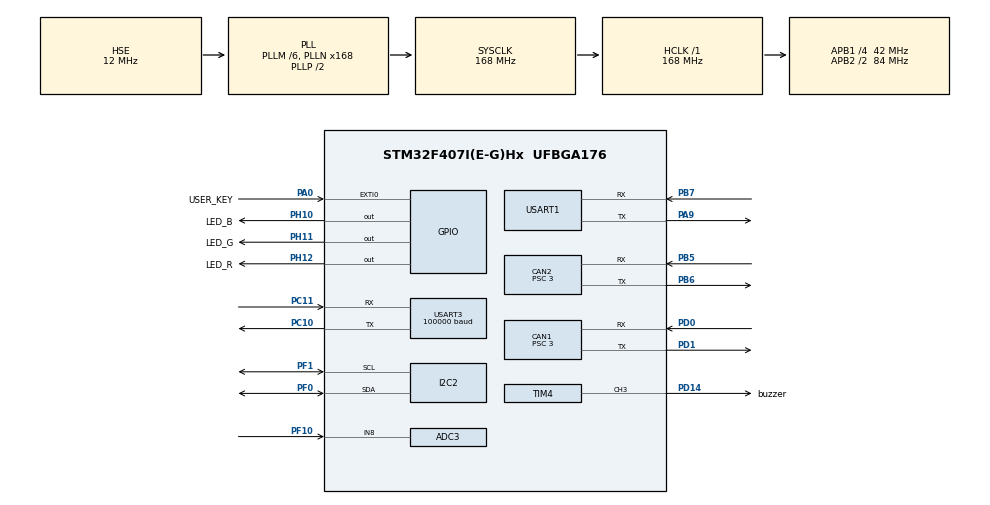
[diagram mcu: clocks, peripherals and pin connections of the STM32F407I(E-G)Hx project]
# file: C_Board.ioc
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ADC1.Channel-0\#ChannelRegularConversion=ADC_CHANNEL_VREFINT
ADC1.NbrOfConversionFlag=1
ADC1.Rank-0\#ChannelRegularConversion=1
ADC1.SamplingTime-0\#ChannelRegularConversion=ADC_SAMPLETIME_3CYCLES
ADC1.master=1
ADC3.Channel-0\#ChannelRegularConversion=ADC_CHANNEL_8
ADC3.NbrOfConversionFlag=1
ADC3.Rank-0\#ChannelRegularConversion=1
ADC3.SamplingTime-0\#ChannelRegularConversion=ADC_SAMPLETIME_3CYCLES
CAN1.BS1=CAN_BS1_10TQ
CAN1.BS2=CAN_BS2_3TQ
CAN1.CalculateTimeQuantum=71.42857142857143
CAN1.Prescaler=3
CAN2.BS1=CAN_BS1_10TQ
CAN2.BS2=CAN_BS2_3TQ
CAN2.CalculateTimeQuantum=71.42857142857143
CAN2.Prescaler=3
Dma.Request0=USART3_RX
Dma.USART3_RX.0.Direction=DMA_PERIPH_TO_MEMORY
Dma.USART3_RX.0.FIFOMode=DMA_FIFOMODE_DISABLE
Dma.USART3_RX.0.Instance=DMA1_Stream1
Dma.USART3_RX.0.MemDataAlignment=DMA_MDATAALIGN_BYTE
Dma.USART3_RX.0.MemInc=DMA_MINC_ENABLE
Dma.USART3_RX.0.Mode=DMA_NORMAL
Dma.USART3_RX.0.PeriphDataAlignment=DMA_PDATAALIGN_BYTE
Dma.USART3_RX.0.PeriphInc=DMA_PINC_DISABLE
Dma.USART3_RX.0.Priority=DMA_PRIORITY_VERY_HIGH
I2C2.I2C_Mode=I2C_Fast
Mcu.Family=STM32F4
Mcu.Name=STM32F407I(E-G)Hx
Mcu.Package=UFBGA176
NVIC.DMA1_Stream1_IRQn=true\:0\:0\:false\:false\:true\:false\:true
NVIC.EXTI0_IRQn=true\:0\:0\:false\:false\:true\:true\:true
NVIC.PriorityGroup=NVIC_PRIORITYGROUP_4
NVIC.TIM1_UP_TIM10_IRQn=true\:0\:0\:false\:false\:true\:true\:true
NVIC.USART3_IRQn=true\:0\:0\:false\:false\:true\:true\:true
PA0-WKUP.GPIO_Label=USER_KEY
PA0-WKUP.GPIO_ModeDefaultEXTI=GPIO_MODE_IT_RISING_FALLING
PA0-WKUP.GPIO_PuPd=GPIO_PULLUP
PA0-WKUP.Signal=GPXTI0
PA13.Mode=Serial_Wire
PA13.Signal=SYS_JTMS-SWDIO
PA14.Mode=Serial_Wire
PA14.Signal=SYS_JTCK-SWCLK
PA9.Mode=Asynchronous
PA9.Signal=USART1_TX
PB5.Mode=Slave
PB5.Signal=CAN2_RX
PB6.Mode=Slave
PB6.Signal=CAN2_TX
PB7.Mode=Asynchronous
PB7.Signal=USART1_RX
PC10.Mode=Asynchronous
PC10.Signal=USART3_TX
PC11.Mode=Asynchronous
PC11.Signal=USART3_RX
PD0.Mode=Master
PD0.Signal=CAN1_RX
PD1.Mode=Master
PD1.Signal=CAN1_TX
PD14.GPIO_Label=buzzer
PD14.Signal=S_TIM4_CH3
PF0.Mode=I2C
PF0.Signal=I2C2_SDA
PF1.Mode=I2C
PF1.Signal=I2C2_SCL
PF10.Mode=IN8
PF10.Signal=ADC3_IN8
PH0-OSC_IN.Mode=HSE-External-Oscillator
PH0-OSC_IN.Signal=RCC_OSC_IN
PH1-OSC_OUT.Mode=HSE-External-Oscillator
PH1-OSC_OUT.Signal=RCC_OSC_OUT
PH10.GPIO_Label=LED_B
PH10.Signal=GPIO_Output
PH11.GPIO_Label=LED_G
PH11.Signal=GPIO_Output
PH12.GPIO_Label=LED_R
PH12.Signal=GPIO_Output
ProjectManager.HeapSize=0x200
ProjectManager.StackSize=0x400
ProjectManager.TargetToolchain=SW4STM32
RCC.48MHZClocksFreq_Value=84000000
RCC.AHBFreq_Value=168000000
RCC.APB1CLKDivider=RCC_HCLK_DIV4
RCC.APB1Freq_Value=42000000
RCC.APB1TimFreq_Value=84000000
RCC.APB2CLKDivider=RCC_HCLK_DIV2
RCC.APB2Freq_Value=84000000
RCC.APB2TimFreq_Value=168000000
RCC.CortexFreq_Value=168000000
RCC.HCLKFreq_Value=168000000
RCC.HSE_VALUE=12000000
RCC.HSI_VALUE=16000000
RCC.LSE_VALUE=32768
RCC.PLLM=6
RCC.PLLN=168
RCC.PLLSourceVirtual=RCC_PLLSOURCE_HSE
RCC.SYSCLKFreq_VALUE=168000000
RCC.SYSCLKSource=RCC_SYSCLKSOURCE_PLLCLK
RCC.VCOOutputFreq_Value=336000000
SH.S_TIM4_CH3.0=TIM4_CH3,PWM Generation3 CH3
TIM1.Period=4999
TIM1.Prescaler=16799
TIM4.Channel-PWM\ Generation3\ CH3=TIM_CHANNEL_3
TIM4.Period=20999
USART1.VirtualMode=VM_ASYNC
USART3.BaudRate=100000
USART3.VirtualMode=VM_ASYNC
VP_ADC1_TempSens_Input.Mode=IN-TempSens
VP_ADC1_Vref_Input.Mode=IN-Vrefint
VP_TIM1_VS_ClockSourceINT.Mode=Internal
VP_TIM4_VS_ClockSourceINT.Mode=Internal
board=custom

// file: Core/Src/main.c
/* USER CODE BEGIN Header */
/**
  ******************************************************************************
  * @file           : main.c
  * @brief          : Main program body
  ******************************************************************************
  * @attention
  *
  * <h2><center>&copy; Copyright (c) 2020 STMicroelectronics.
  * All rights reserved.</center></h2>
  *
  * This software component is licensed by ST under BSD 3-Clause license,
  * the "License"; You may not use this file except in compliance with the
  * License. You may obtain a copy of the License at:
  *                        opensource.org/licenses/BSD-3-Clause
  *
  ******************************************************************************
  */
/* USER CODE END Header */
#include "main.h"
#include "adc.h"
#include "can.h"
#include "dma.h"
#include "i2c.h"
#include "tim.h"
#include "usart.h"
#include "gpio.h"

/* USER CODE BEGIN Includes */
#include "../../APP/remote_control.h"
#include "../../Board_test/bsp_rc.h"
#include "../../Board_test/bsp_usart.h"
#include "../../Board_test/bsp_led.h"
#include "../../Board_test/bsp_adc.h"
#include "../../devices/OLED.h"
#include "../../Board_test/bsp_can.h"
#include "../../APP/CAN_receive.h"
/* USER CODE END Includes */

void SystemClock_Config(void);

int main(void)
{

  /* MCU Configuration--------------------------------------------------------*/

  /* Reset of all peripherals, Initializes the Flash interface and the Systick. */
  HAL_Init();

  /* Configure the system clock */
  SystemClock_Config();

  /* Initialize all configured peripherals */
  MX_GPIO_Init();
  MX_DMA_Init();
  MX_TIM1_Init();
  MX_TIM4_Init();
  MX_USART3_UART_Init();
  MX_ADC1_Init();
  MX_ADC3_Init();
  MX_I2C2_Init();
  MX_CAN1_Init();
  MX_CAN2_Init();
  MX_USART1_UART_Init();
  /* USER CODE BEGIN 2 */
    OLED_init();
    remote_control_init();
//    usart1_tx_dma_init();
    const RC_ctrl_t *local_rc = get_remote_control_point();
    init_vrefint_reciprocal();
    fp32 vol;
    can_filter_init();
  /* USER CODE END 2 */

  /* Infinite loop */
    while (1) {
    if(switch_is_up(local_rc->rc.s[1]))
    {
        if(switch_is_up(local_rc->rc.s[0]))
        {
            CAN_cmd_chassis(1000,1000,1000,1000);
        }
        else if(switch_is_mid(local_rc->rc.s[0]))
        {
            CAN_cmd_chassis(500,500,500,500);
        }
        else
        {
            CAN_cmd_chassis(250,250,250,250);
        }
    }
    else
    {
        CAN_cmd_chassis(0,0,0,0);
    }

    }
}

void SystemClock_Config(void)
{
  RCC_OscInitTypeDef RCC_OscInitStruct = {0};
  RCC_ClkInitTypeDef RCC_ClkInitStruct = {0};

  /** Configure the main internal regulator output voltage
  */
  __HAL_RCC_PWR_CLK_ENABLE();
  __HAL_PWR_VOLTAGESCALING_CONFIG(PWR_REGULATOR_VOLTAGE_SCALE1);
  /** Initializes the RCC Oscillators according to the specified parameters
  * in the RCC_OscInitTypeDef structure.
  */
  RCC_OscInitStruct.OscillatorType = RCC_OSCILLATORTYPE_HSE;
  RCC_OscInitStruct.HSEState = RCC_HSE_ON;
  RCC_OscInitStruct.PLL.PLLState = RCC_PLL_ON;
  RCC_OscInitStruct.PLL.PLLSource = RCC_PLLSOURCE_HSE;
  RCC_OscInitStruct.PLL.PLLM = 6;
  RCC_OscInitStruct.PLL.PLLN = 168;
  RCC_OscInitStruct.PLL.PLLP = RCC_PLLP_DIV2;
  RCC_OscInitStruct.PLL.PLLQ = 4;
  if (HAL_RCC_OscConfig(&RCC_OscInitStruct) != HAL_OK)
  {
    Error_Handler();
  }
  /** Initializes the CPU, AHB and APB buses clocks
  */
  RCC_ClkInitStruct.ClockType = RCC_CLOCKTYPE_HCLK|RCC_CLOCKTYPE_SYSCLK
                              |RCC_CLOCKTYPE_PCLK1|RCC_CLOCKTYPE_PCLK2;
  RCC_ClkInitStruct.SYSCLKSource = RCC_SYSCLKSOURCE_PLLCLK;
  RCC_ClkInitStruct.AHBCLKDivider = RCC_SYSCLK_DIV1;
  RCC_ClkInitStruct.APB1CLKDivider = RCC_HCLK_DIV4;
  RCC_ClkInitStruct.APB2CLKDivider = RCC_HCLK_DIV2;

  if (HAL_RCC_ClockConfig(&RCC_ClkInitStruct, FLASH_LATENCY_5) != HAL_OK)
  {
    Error_Handler();
  }
}

void Error_Handler(void)
{
}

/************************ (C) COPYRIGHT STMicroelectronics *****END OF FILE****/
